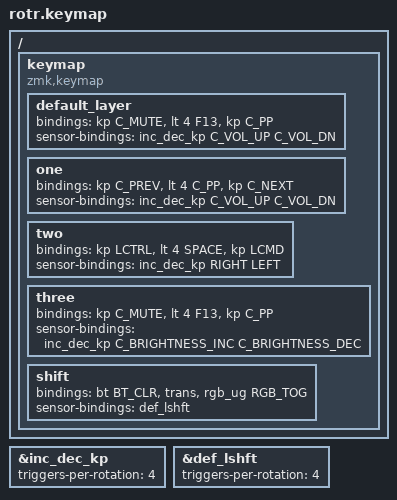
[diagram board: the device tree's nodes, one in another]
#include <behaviors.dtsi>
#include <dt-bindings/zmk/keys.h>
#include <dt-bindings/zmk/rgb.h>
#include <dt-bindings/zmk/bt.h>

&inc_dec_kp {
	triggers-per-rotation = <4>;
};
&def_lshft {
	triggers-per-rotation = <4>;
};

/ {
	keymap {
		compatible = "zmk,keymap";

		default_layer {
			//PREV | PLAY/PAUSE | NEXT
			bindings = <&kp C_MUTE &lt 4 F13 &kp C_PP>;
			sensor-bindings = <&inc_dec_kp C_VOL_UP C_VOL_DN>;
		};
		one {
			//PREV | PLAY/PAUSE | NEXT
			bindings = <&kp C_PREV &lt 4 C_PP &kp C_NEXT>;
			sensor-bindings = <&inc_dec_kp C_VOL_UP C_VOL_DN>;
		};
		two {
			//PREV | PLAY/PAUSE | NEXT
			bindings = <&kp LCTRL &lt 4 SPACE &kp LCMD>;
			sensor-bindings = <&inc_dec_kp RIGHT LEFT>;
		};
		three {
			//PREV | PLAY/PAUSE | NEXT
			bindings = <&kp C_MUTE &lt 4 F13 &kp C_PP>;
			sensor-bindings = <&inc_dec_kp C_BRIGHTNESS_INC C_BRIGHTNESS_DEC>;
		};
		shift {
			//PREV | PLAY/PAUSE | NEXT
			bindings = <&bt BT_CLR &trans &rgb_ug RGB_TOG>;
			sensor-bindings = <&def_lshft>;
		};
	};
};
